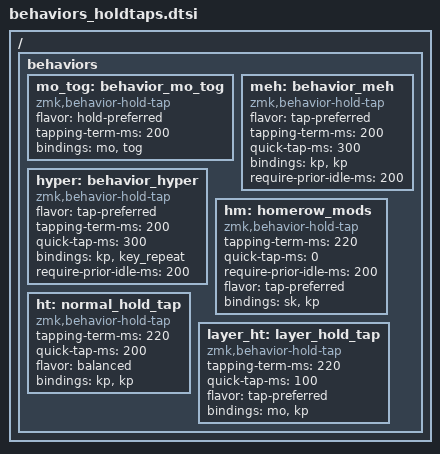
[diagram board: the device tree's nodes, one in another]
 / {

    behaviors {

        mo_tog: behavior_mo_tog {
            compatible = "zmk,behavior-hold-tap";
            #binding-cells = <2>;
            flavor = "hold-preferred";
            tapping-term-ms = <200>;
            bindings = <&mo>, <&tog>;
        };
      
        meh: behavior_meh {
            compatible = "zmk,behavior-hold-tap";
            #binding-cells = <2>;
            flavor = "tap-preferred";
            tapping-term-ms = <200>;
            quick-tap-ms = <300>; // if space is pressed again within 300ms,  holding would trigger space instead of meh
            bindings = <&kp>, <&kp>;
            require-prior-idle-ms = <200>;
        };

        hyper: behavior_hyper {
            compatible = "zmk,behavior-hold-tap";
            #binding-cells = <2>;
            flavor = "tap-preferred";
            tapping-term-ms = <200>;
            quick-tap-ms = <300>; 
            bindings = <&kp>, <&key_repeat>;
            require-prior-idle-ms = <200>;
        };

        hm: homerow_mods {
            compatible = "zmk,behavior-hold-tap";
            #binding-cells = <2>;
            tapping-term-ms = <220>;
            quick-tap-ms = <0>;
            require-prior-idle-ms = <200>;
            flavor = "tap-preferred";
            bindings = <&sk>, <&kp>;
        };

        ht: normal_hold_tap {
            compatible = "zmk,behavior-hold-tap";
            #binding-cells = <2>;
            tapping-term-ms = <220>;
            quick-tap-ms = <200>;
            flavor = "balanced";
            bindings = <&kp>, <&kp>;
        };

        layer_ht: layer_hold_tap {
            compatible = "zmk,behavior-hold-tap";
            #binding-cells = <2>;
            tapping-term-ms = <220>;
            quick-tap-ms = <100>;
            flavor = "tap-preferred";
            bindings = <&mo>, <&kp>;
        };
    };
    
};
